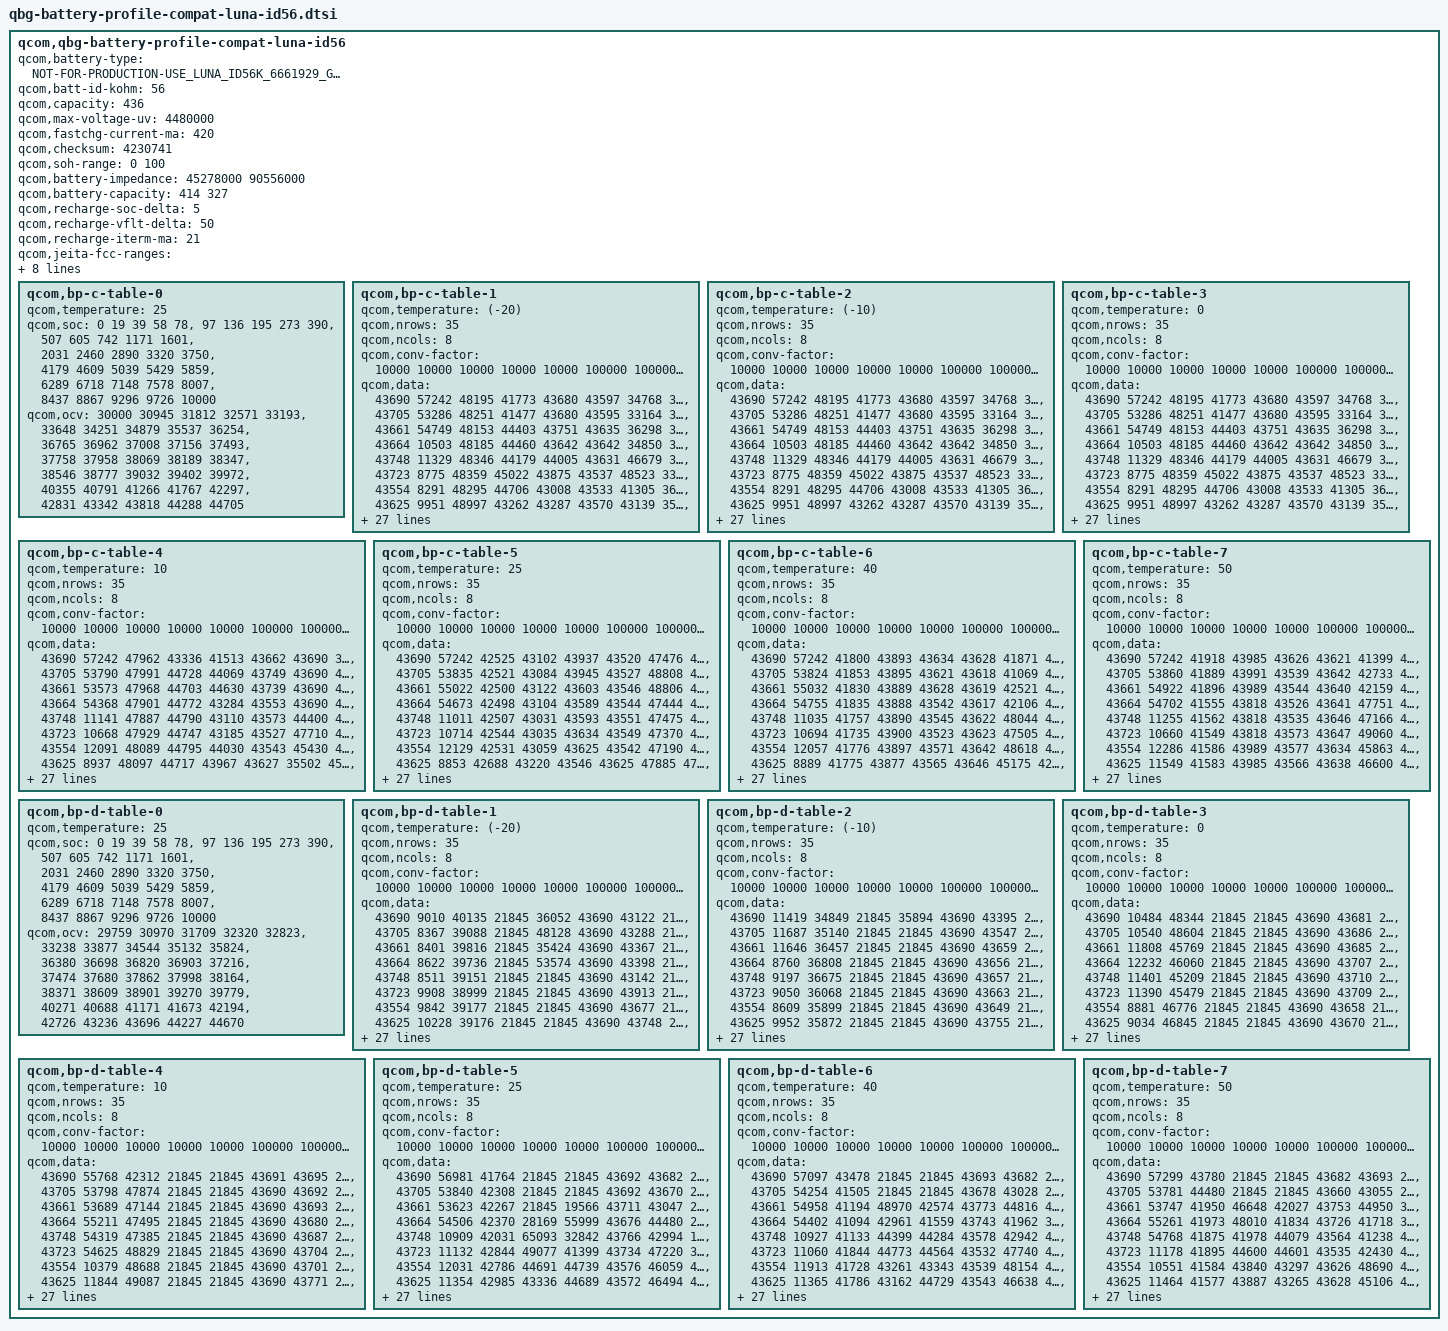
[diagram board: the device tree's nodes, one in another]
/*QBG Profiling Rev. 2.7*/

qcom,qbg-battery-profile-compat-luna-id56 {
	qcom,battery-type = "NOT-FOR-PRODUCTION-USE_LUNA_ID56K_6661929_GOOGLE_420MAH_AVERAGED_MASTERSLAVE_JUL18TH2023_ESR_REV7";
	qcom,batt-id-kohm = <56>;
	qcom,capacity = <436>;
	qcom,max-voltage-uv = <4480000>;
	qcom,fastchg-current-ma = <420>;
	qcom,checksum = <4230741>; /*@5, 0.005V, 4% */
	qcom,soh-range = <0 100>;
	/*Nominal_Impedance in 10nohm @ SOC 50% 25C* 0:fresh cell, 1: aged cell*/
	qcom,battery-impedance = <45278000 90556000>;
	/*Nominal_Capacity in mAh. 0: fresh cell, 1:aged cell*/ 
	qcom,battery-capacity = <414 327>;
	/*SOC delta (in percent) dropped from EOC SOC to enable recharge*/ 
	qcom,recharge-soc-delta =<5>;
	/*vfloat delta (in mV) dropped from regular vfloat in recharge*/ 
	qcom,recharge-vflt-delta =<50>;
	/*termination current (in mA) in recharge*/ 
	qcom,recharge-iterm-ma = <21>;

	qcom,jeita-fcc-ranges = <
				0   100 200000
				100 200 275000
				200 420 500000
				420 460 400000>;

	qcom,jeita-fv-ranges = <
				0   100 4480000
				100 200 4480000
				200 420 4480000
				420 460 4480000>;

	/* COOL = 10 DegC, WARM = 42 DegC */
	qcom,jeita-soft-thresholds = <0x2b8a 0x1444>;
	/* COLD = 0 DegC, HOT = 46 DegC */
	qcom,jeita-hard-thresholds = <0x3257 0x1201>;
	/* COOL = 12 DegC, WARM = 44 DegC */
	qcom,jeita-soft-hys-thresholds = <0x2a0b 0x131C>;
	qcom,jeita-soft-fcc-ua = <200000 200000>;
	qcom,jeita-soft-fv-uv = <4200000 4350000>;

	qcom,bp-c-table-0 {
		qcom,temperature = <25>;
		qcom,soc = <    0    19    39    58    78>,
			<   97   136   195   273   390>,
			<  507   605   742  1171  1601>,
			< 2031  2460  2890  3320  3750>,
			< 4179  4609  5039  5429  5859>,
			< 6289  6718  7148  7578  8007>,
			< 8437  8867  9296  9726 10000>;
		qcom,ocv = <30000 30945 31812 32571 33193>,
			<33648 34251 34879 35537 36254>,
			<36765 36962 37008 37156 37493>,
			<37758 37958 38069 38189 38347>,
			<38546 38777 39032 39402 39972>,
			<40355 40791 41266 41767 42297>,
			<42831 43342 43818 44288 44705>;
	};
	qcom,bp-c-table-1 {
		qcom,temperature = <(-20)>;
		qcom,nrows = <35>;
		qcom,ncols = <8>;
		qcom,conv-factor = <10000 10000 10000 10000 10000 100000 100000 10000>;
		qcom,data = <43690 57242 48195 41773 43680 43597 34768 32772>,
			<43705 53286 48251 41477 43680 43595 33164 32921>,
			<43661 54749 48153 44403 43751 43635 36298 33554>,
			<43664 10503 48185 44460 43642 43642 34850 33685>,
			<43748 11329 48346 44179 44005 43631 46679 33379>,
			<43723  8775 48359 45022 43875 43537 48523 33522>,
			<43554  8291 48295 44706 43008 43533 41305 36141>,
			<43625  9951 48997 43262 43287 43570 43139 35876>,
			<43963  9471 48914 43524 44669 43569 43913 36631>,
			<43820 15002 49008 43715 44652 43524 43938 36447>,
			<43857 14861 48921 43712 44646 43549 43948 36397>,
			<43255 14948 49108 43714 44656 43539 43939 36399>,
			<43084 15275 48992 43531 44549 43616 43917 36564>,
			<44601 14506 49088 44728 43172 43631 41038 36419>,
			<44267 14822 49117 44450 43779 43529 48700 35998>,
			<44357 16111 48705 44291 43846 43572 48179 36040>,
			<41782 15999 48668 41641 43237 43568 47471 36033>,
			<41440 16283 48670 41631 43062 43581 47145 35882>,
			<42578 16184 48850 41669 43086 43583 47172 35871>,
			<41996 15522 48871 41486 43394 43582 48691 35931>,
			<47865 15421 48789 41536 43467 43582 45075 36322>,
			<47275 15658 48796 41893 43491 43582 46573 36332>,
			<47365 13212 48793 41537 43260 43578 48436 36015>,
			<49055 12345 48845 41551 43141 43559 48036 36627>,
			<48201 13990 48770 41873 43249 43564 42939 35972>,
			<45627 14134 48888 41829 43038 43732 41008 36313>,
			<45204 13799 48665 41215 43503 43730 41675 33788>,
			<45382  2993 49046 41086 44693 43743 44085 33126>,
			<46896  2466 48976 41329 44658 43735 44164 33870>,
			<46573  4016 48138 42859 44756 43527 44430 38970>,
			<35423  3504 48562 41339 41377 43734 43499 37436>,
			<34825   907 48396 42699 47827 43733 43034 60027>,
			<36602    83 45737 42644 45556 43563 43157 58817>,
			<36692  1602 45618 41538 35170 43524 43816 62107>,
			<36282  1207 46074 44573 45464 43721 43596 58821>;
	};
	qcom,bp-c-table-2 {
		qcom,temperature = <(-10)>;
		qcom,nrows = <35>;
		qcom,ncols = <8>;
		qcom,conv-factor = <10000 10000 10000 10000 10000 100000 100000 10000>;
		qcom,data = <43690 57242 48195 41773 43680 43597 34768 32772>,
			<43705 53286 48251 41477 43680 43595 33164 32921>,
			<43661 54749 48153 44403 43751 43635 36298 33554>,
			<43664 10503 48185 44460 43642 43642 34850 33685>,
			<43748 11329 48346 44179 44005 43631 46679 33379>,
			<43723  8775 48359 45022 43875 43537 48523 33522>,
			<43554  8291 48295 44706 43008 43533 41305 36141>,
			<43625  9951 48997 43262 43287 43570 43139 35876>,
			<43963  9471 48914 43524 44669 43569 43913 36631>,
			<43820 15002 49008 43715 44652 43524 43938 36447>,
			<43857 14861 48921 43712 44646 43549 43948 36397>,
			<43255 14948 49108 43714 44656 43539 43939 36399>,
			<43084 15275 48992 43531 44549 43616 43917 36564>,
			<44601 14506 49088 44728 43172 43631 41038 36419>,
			<44267 14822 49117 44450 43779 43529 48700 35998>,
			<44357 16111 48705 44291 43846 43572 48179 36040>,
			<41782 15999 48668 41641 43237 43568 47471 36033>,
			<41440 16283 48670 41631 43062 43581 47145 35882>,
			<42578 16184 48850 41669 43086 43583 47172 35871>,
			<41996 15522 48871 41486 43394 43582 48691 35931>,
			<47865 15421 48789 41536 43467 43582 45075 36322>,
			<47275 15658 48796 41893 43491 43582 46573 36332>,
			<47365 13212 48793 41537 43260 43578 48436 36015>,
			<49055 12345 48845 41551 43141 43559 48036 36627>,
			<48201 13990 48770 41873 43249 43564 42939 35972>,
			<45627 14134 48888 41829 43038 43732 41008 36313>,
			<45204 13799 48665 41215 43503 43730 41675 33788>,
			<45382  2993 49046 41086 44693 43743 44085 33126>,
			<46896  2466 48976 41329 44658 43735 44164 33870>,
			<46573  4016 48138 42859 44756 43527 44430 38970>,
			<35423  3504 48562 41339 41377 43734 43499 37436>,
			<34825   907 48396 42699 47827 43733 43034 60027>,
			<36602    83 45737 42644 45556 43563 43157 58817>,
			<36692  1602 45618 41538 35170 43524 43816 62107>,
			<36282  1207 46074 44573 45464 43721 43596 58821>;
	};
	qcom,bp-c-table-3 {
		qcom,temperature = <0>;
		qcom,nrows = <35>;
		qcom,ncols = <8>;
		qcom,conv-factor = <10000 10000 10000 10000 10000 100000 100000 10000>;
		qcom,data = <43690 57242 48195 41773 43680 43597 34768 32772>,
			<43705 53286 48251 41477 43680 43595 33164 32921>,
			<43661 54749 48153 44403 43751 43635 36298 33554>,
			<43664 10503 48185 44460 43642 43642 34850 33685>,
			<43748 11329 48346 44179 44005 43631 46679 33379>,
			<43723  8775 48359 45022 43875 43537 48523 33522>,
			<43554  8291 48295 44706 43008 43533 41305 36141>,
			<43625  9951 48997 43262 43287 43570 43139 35876>,
			<43963  9471 48914 43524 44669 43569 43913 36631>,
			<43820 15002 49008 43715 44652 43524 43938 36447>,
			<43857 14861 48921 43712 44646 43549 43948 36397>,
			<43255 14948 49108 43714 44656 43539 43939 36399>,
			<43084 15275 48992 43531 44549 43616 43917 36564>,
			<44601 14506 49088 44728 43172 43631 41038 36419>,
			<44267 14822 49117 44450 43779 43529 48700 35998>,
			<44357 16111 48705 44291 43846 43572 48179 36040>,
			<41782 15999 48668 41641 43237 43568 47471 36033>,
			<41440 16283 48670 41631 43062 43581 47145 35882>,
			<42578 16184 48850 41669 43086 43583 47172 35871>,
			<41996 15522 48871 41486 43394 43582 48691 35931>,
			<47865 15421 48789 41536 43467 43582 45075 36322>,
			<47275 15658 48796 41893 43491 43582 46573 36332>,
			<47365 13212 48793 41537 43260 43578 48436 36015>,
			<49055 12345 48845 41551 43141 43559 48036 36627>,
			<48201 13990 48770 41873 43249 43564 42939 35972>,
			<45627 14134 48888 41829 43038 43732 41008 36313>,
			<45204 13799 48665 41215 43503 43730 41675 33788>,
			<45382  2993 49046 41086 44693 43743 44085 33126>,
			<46896  2466 48976 41329 44658 43735 44164 33870>,
			<46573  4016 48138 42859 44756 43527 44430 38970>,
			<35423  3504 48562 41339 41377 43734 43499 37436>,
			<34825   907 48396 42699 47827 43733 43034 60027>,
			<36602    83 45737 42644 45556 43563 43157 58817>,
			<36692  1602 45618 41538 35170 43524 43816 62107>,
			<36282  1207 46074 44573 45464 43721 43596 58821>;
	};
	qcom,bp-c-table-4 {
		qcom,temperature = <10>;
		qcom,nrows = <35>;
		qcom,ncols = <8>;
		qcom,conv-factor = <10000 10000 10000 10000 10000 100000 100000 10000>;
		qcom,data = <43690 57242 47962 43336 41513 43662 43690 35551>,
			<43705 53790 47991 44728 44069 43749 43690 46414>,
			<43661 53573 47968 44703 44630 43739 43690 46591>,
			<43664 54368 47901 44772 43284 43553 43690 46178>,
			<43748 11141 47887 44790 43110 43573 44400 46229>,
			<43723 10668 47929 44747 43185 43527 47710 46865>,
			<43554 12091 48089 44795 44030 43543 45430 46691>,
			<43625  8937 48097 44717 43967 43627 35502 45324>,
			<43963  8638 48012 43963 43484 43559 43265 45104>,
			<43820 10066 47701 43797 43221 43598 43246 45896>,
			<43857  9539 47718 43810 43042 43609 43247 45980>,
			<43255 14883 47647 43720 43324 43913 43961 45636>,
			<43084 14864 47668 43965 43103 43952 43815 45589>,
			<44601 15309 47630 44728 43965 43626 47234 45852>,
			<44267 14446 47862 44978 43993 43533 47456 45271>,
			<44357 14688 47771 45045 43887 43532 48997 45108>,
			<41782 15905 47800 44858 43903 43529 49030 45265>,
			<41440 15949 42340 44826 43179 43528 48645 45254>,
			<42578 16380 42255 44821 43187 43531 47337 45285>,
			<41996 16205 42279 44824 43210 43530 42872 45259>,
			<47865 15417 42450 44828 43113 43572 42786 45116>,
			<47275 15871 42440 44912 43406 43572 47725 45140>,
			<47365 12862 42447 44193 43130 43572 46061 45154>,
			<49055 12539 42438 44193 43840 43573 45452 45830>,
			<48201 13963 42373 44807 43880 43571 41319 46008>,
			<45627 14086 42422 44867 43846 43582 40974 46028>,
			<45204 13813 42478 44175 43190 43557 41859 45889>,
			<45382  2971 42375 44093 43142 43553 41740 45274>,
			<46896  2447 42468 44441 43013 43566 41659 45377>,
			<46573  3993 42348 44302 43269 43560 44196 46254>,
			<35423  3558 47772 41661 44941 43561 44632 35347>,
			<34825  1016 47661 41670 44315 43565 44735 36381>,
			<36602   411 47683 41695 42951 43579 43400 33133>,
			<36692  1962 48091 44465 47269 43559 43118 39434>,
			<36282  1241 47153 43434 48039 43552 43962 34644>;
	};
	qcom,bp-c-table-5 {
		qcom,temperature = <25>;
		qcom,nrows = <35>;
		qcom,ncols = <8>;
		qcom,conv-factor = <10000 10000 10000 10000 10000 100000 100000 10000>;
		qcom,data = <43690 57242 42525 43102 43937 43520 47476 47106>,
			<43705 53835 42521 43084 43945 43527 48808 47327>,
			<43661 55022 42500 43122 43603 43546 48806 47337>,
			<43664 54673 42498 43104 43589 43544 47444 47291>,
			<43748 11011 42507 43031 43593 43551 47475 47947>,
			<43723 10714 42544 43035 43634 43549 47370 47896>,
			<43554 12129 42531 43059 43625 43542 47190 48119>,
			<43625  8853 42688 43220 43546 43625 47885 47709>,
			<43963  8315 42652 43215 43522 43617 42006 47666>,
			<43820 10036 42684 43258 43520 43641 42172 47870>,
			<43857  9527 42671 43191 43542 43638 41186 47780>,
			<43255 15048 41283 43170 43520 43632 41801 42349>,
			<43084 14906 41331 43136 43583 43644 42371 42257>,
			<44601 15246 41315 43042 43941 43628 42551 47662>,
			<44267 14559 41225 43083 44001 43540 41984 47682>,
			<44357 14804 41428 43434 43984 43626 42334 48046>,
			<41782 16108 41422 43447 43980 43536 47220 47687>,
			<41440 15903 41452 43395 43977 43539 47605 47738>,
			<42578 16263 41395 43490 43983 43549 48098 47727>,
			<41996 16225 41382 43490 43828 43539 42669 47705>,
			<47865 15416 41042 43082 43259 43551 44038 48008>,
			<47275 15827 41084 43129 43111 43524 44101 48116>,
			<47365 13010 41066 43420 43130 43550 47712 47891>,
			<49055 13120 40985 43513 43233 43549 47471 48126>,
			<48201 13966 40975 43077 43969 43546 41496 42308>,
			<45627 14089 41010 43435 43814 43524 44347 47807>,
			<45204 13821 41018 43431 43887 43523 44194 47857>,
			<45382  2968 41019 43499 43844 43534 44809 47638>,
			<46896  2445 41021 43283 43864 43535 44083 48097>,
			<46573  3987 41013 43353 43149 43528 44212 47999>,
			<35423  3557 40989 44764 43033 43573 44913 47530>,
			<34825   996 41036 44610 43295 43529 44843 48668>,
			<36602   384 41393 44627 44278 43546 44762 48495>,
			<36692  1962 41251 43367 44616 43550 44904 49093>,
			<36282  1035 42726 43156 41310 43528 43823 46778>;
	};
	qcom,bp-c-table-6 {
		qcom,temperature = <40>;
		qcom,nrows = <35>;
		qcom,ncols = <8>;
		qcom,conv-factor = <10000 10000 10000 10000 10000 100000 100000 10000>;
		qcom,data = <43690 57242 41800 43893 43634 43628 41871 42983>,
			<43705 53824 41853 43895 43621 43618 41069 42911>,
			<43661 55032 41830 43889 43628 43619 42521 42932>,
			<43664 54755 41835 43888 43542 43617 42106 42924>,
			<43748 11035 41757 43890 43545 43622 48044 42564>,
			<43723 10694 41735 43900 43523 43623 47505 42610>,
			<43554 12057 41776 43897 43571 43642 48618 42501>,
			<43625  8889 41775 43877 43565 43646 45175 42538>,
			<43963  8252 41947 43878 43728 43634 46650 42736>,
			<43820 10184 41975 43788 43733 43593 48005 42679>,
			<43857  9679 41978 43821 43554 43608 42450 41298>,
			<43255 15083 41964 44014 43578 43605 41244 41218>,
			<43084 15068 41963 44026 43567 43614 42116 41216>,
			<44601 14942 41873 43822 43965 43589 41623 42716>,
			<44267 14485 41863 43794 43905 43599 41026 42527>,
			<44357 14831 41864 43874 44018 43599 42638 42563>,
			<41782 16058 41913 43875 44015 43637 42483 42593>,
			<41440 15885 41902 43881 43967 43634 42404 42529>,
			<42578 16260 41561 43844 43966 43620 42869 42522>,
			<41996 16254 41549 43138 43923 43622 41059 42924>,
			<47865 15414 41587 43171 43797 43635 44094 42946>,
			<47275 15661 41575 43822 43013 43636 44584 42768>,
			<47365 12852 41577 43830 43030 43645 44492 42862>,
			<49055 12468 41491 43792 43858 43647 41962 42898>,
			<48201 13963 41499 43778 43956 43633 41655 42650>,
			<45627 14093 41473 43793 43931 43645 44113 42744>,
			<45204 13812 41485 43893 44028 43643 44259 42506>,
			<45382  2963 41487 43189 43995 43619 44065 42921>,
			<46896  2462 41485 43239 43784 43624 44169 42950>,
			<46573  4079 41478 43206 43849 43540 45014 42866>,
			<35423  3580 41497 43116 43188 43544 44807 42196>,
			<34825   994 41578 43419 43046 43537 44217 42447>,
			<36602   434 41597 43503 43365 43643 44812 47689>,
			<36692  1622 41896 43143 43059 43619 44810 42033>,
			<36282  1054 41809 43964 41504 43941 43982 48863>;
	};
	qcom,bp-c-table-7 {
		qcom,temperature = <50>;
		qcom,nrows = <35>;
		qcom,ncols = <8>;
		qcom,conv-factor = <10000 10000 10000 10000 10000 100000 100000 10000>;
		qcom,data = <43690 57242 41918 43985 43626 43621 41399 41302>,
			<43705 53860 41889 43991 43539 43642 42733 41280>,
			<43661 54922 41896 43989 43544 43640 42159 41331>,
			<43664 54702 41555 43818 43526 43641 47751 41315>,
			<43748 11255 41562 43818 43535 43646 47166 41235>,
			<43723 10660 41549 43818 43573 43647 49060 41219>,
			<43554 12286 41586 43989 43577 43634 45863 41249>,
			<43625 11549 41583 43985 43566 43638 46600 41419>,
			<43963  8426 41502 43973 43736 43593 46778 41349>,
			<43820 10146 41486 43981 43719 43587 45090 41383>,
			<43857  9656 41522 44030 43712 43603 45778 41033>,
			<43255 15019 41528 43948 43738 43966 42298 40997>,
			<43084 15082 41507 43613 43732 43961 42613 40995>,
			<44601 14878 41513 44030 43587 43945 41931 41458>,
			<44267 14504 41680 44004 43941 43945 41776 41408>,
			<44357 14754 41691 43982 43927 43945 41352 41216>,
			<41782 14719 41677 44020 44013 43947 42976 41216>,
			<41440 15908 41718 44001 43614 43602 42840 41367>,
			<42578 16266 41720 43984 43591 43596 42165 41411>,
			<41996 16230 41699 43795 43962 43632 41366 41312>,
			<47865 15410 41706 43874 43983 43597 44505 42651>,
			<47275 15648 41629 43953 43217 43942 43280 42707>,
			<47365 12806 41605 43960 43064 43605 44933 42717>,
			<49055 12421 41603 43923 43880 43615 41624 41329>,
			<48201 13960 41608 44015 43589 43602 41559 41045>,
			<45627 14087 41655 44029 43606 43588 44340 41355>,
			<45204 13773 41651 43986 43913 43596 44060 41412>,
			<45382  3055 41650 43785 44000 43637 44272 41325>,
			<46896  2452 41661 43846 43979 43644 44512 42628>,
			<46573  4071 41648 43175 43839 43621 44063 42535>,
			<35423  3570 41652 43246 43807 43618 44435 42561>,
			<34825   994 41612 43217 43190 43628 44063 42800>,
			<36602   444 41629 43050 43443 43616 44847 41996>,
			<36692  1620 41703 43887 43176 43637 44188 42621>,
			<36282  1043 41868 43927 44536 43915 43786 47319>;
	};
	qcom,bp-d-table-0 {
		qcom,temperature = <25>;
		qcom,soc = <    0    19    39    58    78>,
			<   97   136   195   273   390>,
			<  507   605   742  1171  1601>,
			< 2031  2460  2890  3320  3750>,
			< 4179  4609  5039  5429  5859>,
			< 6289  6718  7148  7578  8007>,
			< 8437  8867  9296  9726 10000>;
		qcom,ocv = <29759 30970 31709 32320 32823>,
			<33238 33877 34544 35132 35824>,
			<36380 36698 36820 36903 37216>,
			<37474 37680 37862 37998 38164>,
			<38371 38609 38901 39270 39779>,
			<40271 40688 41171 41673 42194>,
			<42726 43236 43696 44227 44670>;
	};
	qcom,bp-d-table-1 {
		qcom,temperature = <(-20)>;
		qcom,nrows = <35>;
		qcom,ncols = <8>;
		qcom,conv-factor = <10000 10000 10000 10000 10000 100000 100000 10000>;
		qcom,data = <43690  9010 40135 21845 36052 43690 43122 21845>,
			<43705  8367 39088 21845 48128 43690 43288 21845>,
			<43661  8401 39816 21845 35424 43690 43367 21845>,
			<43664  8622 39736 21845 53574 43690 43398 21845>,
			<43748  8511 39151 21845 21845 43690 43142 21845>,
			<43723  9908 38999 21845 21845 43690 43913 21845>,
			<43554  9842 39177 21845 21845 43690 43677 21845>,
			<43625 10228 39176 21845 21845 43690 43748 21845>,
			<43963 10049 39188 21845 14930 43690 43563 21845>,
			<43820  9265 39186 21845 61034 43690 43605 21845>,
			<43857  9652 39652 21845 36108 43690 43788 21845>,
			<43255  9667 34266 21845 46694 43690 43840 21845>,
			<43084  9592 34409 13414 48682 43691 43069 21845>,
			<44601 14864 33614 64666 47230 43688 43314 21845>,
			<44267 15323 36124 37258 48059 43689 44729 32151>,
			<44357 14511 36263 33181 42849 43694 44793  1291>,
			<41782 14389 36389 35795 40963 43695 44988 15906>,
			<41440 14748 35202 45160 41693 43693 44896 10972>,
			<42578 14713 35658 48964 44471 43683 44195 56077>,
			<41996 16082 35837 47259 44067 43681 44897 52289>,
			<47865 16263 35775 47757 44180 43686 45012 52087>,
			<47275 16211 35429 42432 44877 43687 44879 51954>,
			<47365 15424 35435 42060 45004 43706 44452 62881>,
			<49055 12960 35358 42080 44959 43705 41919 62690>,
			<48201 13068 35346 42785 44613 43719 47631 62679>,
			<45627 12736 35754 42946 44947 43557 47140 62902>,
			<45204 14324 35419 42840 44193 43583 47599 62839>,
			<45382 13610 35375 42033 44154 43581 47384 51717>,
			<46896  2827 35536 42488 44492 43577 47336 51987>,
			<46573  2429 35576 47774 44410 43556 47346 51263>,
			<35423  3926 35565 47731 41621 43566 47769 51480>,
			<34825   687 35482 47909 41625 43731 42946 52948>,
			<36602   850 35466 47926 44480 43712 41190 52989>,
			<36692  1578 35507 48052 44995 43762 44108 51646>,
			<36282  1040 35510 47855 44599 43745 44595 51972>;
	};
	qcom,bp-d-table-2 {
		qcom,temperature = <(-10)>;
		qcom,nrows = <35>;
		qcom,ncols = <8>;
		qcom,conv-factor = <10000 10000 10000 10000 10000 100000 100000 10000>;
		qcom,data = <43690 11419 34849 21845 35894 43690 43395 21845>,
			<43705 11687 35140 21845 21845 43690 43547 21845>,
			<43661 11646 36457 21845 21845 43690 43659 21845>,
			<43664  8760 36808 21845 21845 43690 43656 21845>,
			<43748  9197 36675 21845 21845 43690 43657 21845>,
			<43723  9050 36068 21845 21845 43690 43663 21845>,
			<43554  8609 35899 21845 21845 43690 43649 21845>,
			<43625  9952 35872 21845 21845 43690 43755 21845>,
			<43963  9992 35970 21845 56634 43690 43580 21845>,
			<43820  9316 36828 21845 36234 43690 43832 21845>,
			<43857  9721 35253  3867 47166 43690 43227 21845>,
			<43255  9478 35781 65180 41235 43691 43299 21845>,
			<43084 15012 46342 33020 44344 43688 44630  8115>,
			<44601 14919 46998 47125 44948 43695 44052 50887>,
			<44267 15139 45468 47626 44940 43683 44465 61447>,
			<44357 14525 45261 42171 44573 43687 44128 64355>,
			<41782 14342 45256 42708 44732 43705 44385 59385>,
			<41440 14827 45276 40961 43369 43700 44362 57505>,
			<42578 14706 45266 41872 43498 43775 41504 60730>,
			<41996 15912 45278 41579 43120 43564 41109 61205>,
			<47865 16369 45276 41571 43134 43552 42593 60929>,
			<47275 15392 45272 41976 43084 43580 48150 61176>,
			<47365 15738 45272 41971 43317 43571 48748 61161>,
			<49055 13219 45152 41939 44707 43575 47880 61157>,
			<48201 12336 45114 41795 44761 43530 48069 61150>,
			<45627 14020 45310 41011 44629 43573 47916 61040>,
			<45204 13511 45280 41468 44850 43571 47707 61199>,
			<45382  2601 45288 42635 44223 43579 42350 60430>,
			<46896  2073 45191 42580 44074 43565 42345 60715>,
			<46573  3683 45255 42814 44140 43735 42873 58091>,
			<35423  3194 45303 42164 44104 43737 42745 58272>,
			<34825   540 45310 42031 44063 43719 41072 58163>,
			<36602   217 45291 42196 44922 43721 41763 58350>,
			<36692  1561 45237 42832 43380 43775 41667 60698>,
			<36282  1040 45219 42980 43128 43745 44389 60457>;
	};
	qcom,bp-d-table-3 {
		qcom,temperature = <0>;
		qcom,nrows = <35>;
		qcom,ncols = <8>;
		qcom,conv-factor = <10000 10000 10000 10000 10000 100000 100000 10000>;
		qcom,data = <43690 10484 48344 21845 21845 43690 43681 21845>,
			<43705 10540 48604 21845 21845 43690 43686 21845>,
			<43661 11808 45769 21845 21845 43690 43685 21845>,
			<43664 12232 46060 21845 21845 43690 43707 21845>,
			<43748 11401 45209 21845 21845 43690 43710 21845>,
			<43723 11390 45479 21845 21845 43690 43709 21845>,
			<43554  8881 46776 21845 21845 43690 43658 21845>,
			<43625  9034 46845 21845 21845 43690 43670 21845>,
			<43963  8522 46765 21845 62569 43690 43571 21845>,
			<43820  9396 45196 25430 49113 43690 43889 21845>,
			<43857  9604 45649 38815 41886 43691 43336 30628>,
			<43255  9515 45583 45074 45046 43688 44842 14931>,
			<43084  9582 48387 42614 43454 43695 44377 63286>,
			<44601 14886 48189 44458 43243 43699 41968 38070>,
			<44267 15113 48998 44489 43025 43768 47719 37266>,
			<44357 14345 49145 44420 43089 43578 45235 40388>,
			<41782 14725 49032 44107 43083 43570 48332 40682>,
			<41440 14601 49038 44084 43047 43575 47125 39803>,
			<42578 16055 49129 44253 43157 43573 48035 34112>,
			<41996 15968 49094 44252 43144 43528 47307 33891>,
			<47865 16224 49094 44045 43231 43533 45582 33990>,
			<47275 15465 49024 44077 43128 43535 48109 34662>,
			<47365 15705 49078 44055 43429 43521 42319 34783>,
			<49055 13212 49083 44465 43489 43520 42278 34602>,
			<48201 12413 49084 44300 43265 43534 42277 34650>,
			<45627 13844 49084 41701 44691 43572 42341 33910>,
			<45204 13436 48720 41899 44646 43581 42361 34147>,
			<45382  2629 48757 41763 44929 43559 42134 39456>,
			<46896  2142 48743 41828 45045 43560 41457 39517>,
			<46573  3676 48726 41815 45042 43729 41941 39921>,
			<35423  3152 48642 41140 44928 43743 41589 39883>,
			<34825   576 48749 41197 44618 43737 41874 39719>,
			<36602    14 48760 41089 44700 43717 41770 39925>,
			<36692  1645 48665 41783 43090 43714 41943 39633>,
			<36282  1050 48854 41875 43137 43721 41963 34125>;
	};
	qcom,bp-d-table-4 {
		qcom,temperature = <10>;
		qcom,nrows = <35>;
		qcom,ncols = <8>;
		qcom,conv-factor = <10000 10000 10000 10000 10000 100000 100000 10000>;
		qcom,data = <43690 55768 42312 21845 21845 43691 43695 21845>,
			<43705 53798 47874 21845 21845 43690 43692 21845>,
			<43661 53689 47144 21845 21845 43690 43693 21845>,
			<43664 55211 47495 21845 21845 43690 43680 21845>,
			<43748 54319 47385 21845 21845 43690 43687 21845>,
			<43723 54625 48829 21845 21845 43690 43704 21845>,
			<43554 10379 48688 21845 21845 43690 43701 21845>,
			<43625 11844 49087 21845 21845 43690 43771 21845>,
			<43963 11619 48665 21845 57726 43690 43950 21845>,
			<43820  8608 47442 57628 42665 43691 43312 19580>,
			<43857 10017 47218 47291 44675 43689 44327 56178>,
			<43255  9306 47253 41895 43104 43681 41346 61043>,
			<43084  9517 47878 44848 43243 43754 41407 39300>,
			<44601 15030 48065 43353 44018 43733 41322 36476>,
			<44267 15305 48003 44572 43856 43569 42365 35086>,
			<44357 14556 47621 44671 43052 43520 48005 35701>,
			<41782 14733 47629 44668 43056 43544 47929 35580>,
			<41440 14640 47716 44573 43137 43545 47760 46191>,
			<42578 16002 47677 44572 43864 43547 47267 46923>,
			<41996 15961 47621 44566 43191 43550 48832 47067>,
			<47865 16232 47670 44571 43166 43551 47761 46674>,
			<47275 15390 47678 44649 43161 43551 42817 46653>,
			<47365 15690 47809 44638 43240 43544 42238 46638>,
			<49055 13188 47847 44947 43230 43525 42460 46598>,
			<48201 12381 47845 44804 43092 43546 47265 46880>,
			<45627 14244 47859 44180 43387 43546 47449 46151>,
			<45204 13757 47771 44074 44775 43533 47797 46341>,
			<45382  2651 47750 44248 44793 43571 41018 46356>,
			<46896  2115 47757 44073 44681 43582 41677 46403>,
			<46573  3676 47750 44053 43286 43579 41518 35493>,
			<35423  3490 47771 44148 43479 43556 41896 35530>,
			<34825   593 47765 44155 43511 43558 41930 35345>,
			<36602    18 47844 44041 43452 43553 41847 35425>,
			<36692  1636 47858 44285 43225 43555 40991 35350>,
			<36282  1036 47862 44169 43198 43555 41441 35336>;
	};
	qcom,bp-d-table-5 {
		qcom,temperature = <25>;
		qcom,nrows = <35>;
		qcom,ncols = <8>;
		qcom,conv-factor = <10000 10000 10000 10000 10000 100000 100000 10000>;
		qcom,data = <43690 56981 41764 21845 21845 43692 43682 21845>,
			<43705 53840 42308 21845 21845 43692 43670 21845>,
			<43661 53623 42267 21845 19566 43711 43047 21845>,
			<43664 54506 42370 28169 55999 43676 44480 21845>,
			<43748 10909 42031 65093 32842 43766 42994 10854>,
			<43723 11132 42844 49077 41399 43734 47220 33882>,
			<43554 12031 42786 44691 44739 43576 46059 45349>,
			<43625 11354 42985 43336 44689 43572 46494 45828>,
			<43963  9110 42915 43308 43439 43535 35398 48218>,
			<43820  8538 42498 43498 43788 43520 46455 48771>,
			<43857  9398 42689 43089 43907 43551 48321 47210>,
			<43255  9712 42747 43438 43985 43544 40967 47214>,
			<43084  9598 42751 43099 43914 43537 42191 47283>,
			<44601 14989 42662 43257 43570 43628 48376 47864>,
			<44267 15306 41315 43057 44025 43541 41324 47700>,
			<44357 14536 41273 43017 43804 43619 41222 48057>,
			<41782 14746 41435 43115 43183 43620 42961 48099>,
			<41440 14668 41463 43078 43137 43647 47891 48086>,
			<42578 16068 41366 43014 43146 43622 41318 47699>,
			<41996 16318 41346 43018 43900 43622 41214 47654>,
			<47865 16201 41402 43028 43819 43616 42502 47773>,
			<47275 15483 41046 43022 43981 43624 41259 42314>,
			<47365 15711 41033 43013 43981 43625 42599 42358>,
			<49055 13260 41082 43089 43807 43617 47124 47857>,
			<48201 12745 41066 43501 43109 43620 49057 47981>,
			<45627 14309 40987 43502 43486 43624 42952 47350>,
			<45204 13402 40972 43455 43398 43551 41704 47989>,
			<45382  2681 40973 43487 43229 43630 41597 47926>,
			<46896  2147 40971 43292 43878 43630 40971 48024>,
			<46573  3704 40965 43276 43984 43542 41025 47694>,
			<35423  3148 41065 43296 44011 43539 42534 47631>,
			<34825   590 41072 43513 44008 43540 42532 47662>,
			<36602    26 41055 43448 44018 43630 41312 47828>,
			<36692  1641 41404 43133 43988 43629 41000 47828>,
			<36282  1236 41351 43033 43826 43618 41739 47829>;
	};
	qcom,bp-d-table-6 {
		qcom,temperature = <40>;
		qcom,nrows = <35>;
		qcom,ncols = <8>;
		qcom,conv-factor = <10000 10000 10000 10000 10000 100000 100000 10000>;
		qcom,data = <43690 57097 43478 21845 21845 43693 43682 21845>,
			<43705 54254 41505 21845 21845 43678 43028 21845>,
			<43661 54958 41194 48970 42574 43773 44816 40847>,
			<43664 54402 41094 42961 41559 43743 41962 36800>,
			<43748 10927 41133 44399 44284 43578 42942 45077>,
			<43723 11060 41844 44773 44564 43532 47740 48891>,
			<43554 11913 41728 43261 43343 43539 48154 47724>,
			<43625 11365 41786 43162 44729 43543 46638 47619>,
			<43963  9142 41938 43190 43323 43624 35816 42313>,
			<43820  8481 41975 43174 43886 43618 35641 42829>,
			<43857  9985 41958 43869 43585 43643 46205 42614>,
			<43255  9661 41967 43199 43605 43617 42513 42939>,
			<43084  9573 41877 43163 43601 43619 42919 42883>,
			<44601 15032 41861 43977 43566 43590 47136 41244>,
			<44267 15258 41919 43793 43615 43584 42897 42691>,
			<44357 14470 41899 43776 43935 43610 41043 42539>,
			<41782 14755 41554 43781 43819 43608 41239 42594>,
			<41440 14682 41541 43876 43192 43600 40989 42950>,
			<42578 15928 41545 43178 43876 43938 42634 43005>,
			<41996 16360 41596 43852 43789 43610 41263 42924>,
			<47865 15521 41569 43900 44016 43589 41296 42506>,
			<47275 15454 41579 43781 43918 43584 41418 42652>,
			<47365 12990 41501 43779 43910 43586 42662 42655>,
			<49055 13087 41476 43853 43844 43615 47757 42902>,
			<48201 12570 41486 43191 43075 43602 42295 42226>,
			<45627 14314 41524 43195 43133 43586 44307 42217>,
			<45204 13394 41521 43107 43800 43966 41036 42842>,
			<45382  2661 41521 43079 43908 43590 42911 42785>,
			<46896  2158 41527 43014 43949 43623 42694 42883>,
			<46573  3706 41483 43050 43633 43627 42006 42617>,
			<35423  3146 41487 43234 43622 43630 42315 42534>,
			<34825   624 41479 43173 43621 43620 42255 42747>,
			<36602     3 41490 43888 43596 43638 42118 42646>,
			<36692  1552 41583 43777 43958 43584 41388 42646>,
			<36282  1216 41572 43834 43920 43609 41859 42721>;
	};
	qcom,bp-d-table-7 {
		qcom,temperature = <50>;
		qcom,nrows = <35>;
		qcom,ncols = <8>;
		qcom,conv-factor = <10000 10000 10000 10000 10000 100000 100000 10000>;
		qcom,data = <43690 57299 43780 21845 21845 43682 43693 21845>,
			<43705 53781 44480 21845 21845 43660 43055 21845>,
			<43661 53747 41950 46648 42027 43753 44950 38663>,
			<43664 55261 41973 48010 41834 43726 41718 33571>,
			<43748 54768 41875 41978 44079 43564 41238 45431>,
			<43723 11178 41895 44600 44601 43535 42430 47412>,
			<43554 10551 41584 43840 43297 43626 48690 42422>,
			<43625 11464 41577 43887 43265 43628 45106 42065>,
			<43963  8825 41476 43801 43458 43622 35428 42193>,
			<43820  8684 41522 43779 43866 43641 35059 42570>,
			<43857 10236 41507 43837 43614 43633 46429 41234>,
			<43255  9324 41512 43803 43642 43641 47766 41242>,
			<43084  9481 41514 43851 43589 43623 42210 42658>,
			<44601  9536 41682 43952 43717 43946 48299 41022>,
			<44267 15275 41679 43996 43629 43946 47810 41360>,
			<44357 14506 41712 43971 43606 43942 42944 41469>,
			<41782 14411 41726 43969 43930 43964 42226 41259>,
			<41440 14667 41700 43832 43885 43959 40965 42645>,
			<42578 15885 41711 43827 43859 43964 41788 42714>,
			<41996 16382 41623 43778 43834 43965 41114 42683>,
			<47865 15537 41628 43833 43935 43940 41064 41267>,
			<47275 15788 41604 43996 43610 43949 43003 41351>,
			<47365 12931 41613 43976 43605 43947 42179 41350>,
			<49055 13073 41610 43999 43877 43946 42804 42662>,
			<48201 12544 41651 43901 43231 43953 41080 42915>,
			<45627 14318 41663 43252 43881 44026 41199 42921>,
			<45204 13404 41657 43021 43965 43960 42866 42548>,
			<45382  2661 41656 43225 43590 43633 42807 42645>,
			<46896  2159 41656 43234 43542 43619 48107 41292>,
			<46573  3684 41662 43198 43530 43622 48772 41276>,
			<35423  3186 41660 43804 43551 43645 42237 41441>,
			<34825   613 41648 43827 43521 43598 47879 41407>,
			<36602    10 41653 43989 43551 43614 47297 41383>,
			<36692  1541 41602 44026 43607 43938 41767 41400>,
			<36282  1276 41604 43930 43909 43965 43690 41392>;
	};
};
